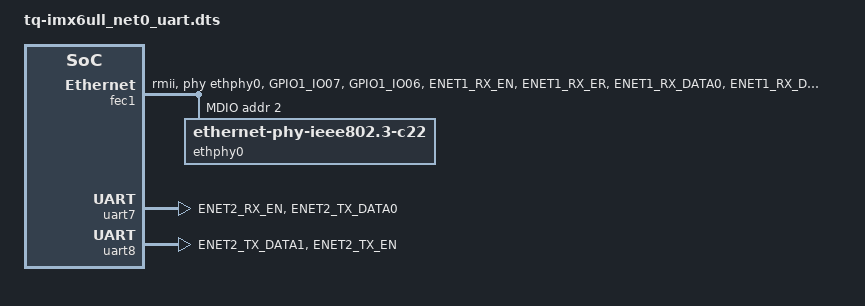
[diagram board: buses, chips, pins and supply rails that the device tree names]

#include "tq-imx6ull.dts"

&iomuxc {
	imx6ul-evk {
		pinctrl_enet1: enet1grp {
			fsl,pins = <
				MX6UL_PAD_GPIO1_IO07__ENET1_MDC		0x1b0b0
				MX6UL_PAD_GPIO1_IO06__ENET1_MDIO	0x1b0b0

				MX6UL_PAD_ENET1_RX_EN__ENET1_RX_EN	0x1b0b0
				MX6UL_PAD_ENET1_RX_ER__ENET1_RX_ER	0x1b0b0
				MX6UL_PAD_ENET1_RX_DATA0__ENET1_RDATA00	0x1b0b0
				MX6UL_PAD_ENET1_RX_DATA1__ENET1_RDATA01	0x1b0b0
				MX6UL_PAD_ENET1_TX_EN__ENET1_TX_EN	0x1b0b0
				MX6UL_PAD_ENET1_TX_DATA0__ENET1_TDATA00	0x1b0b0
				MX6UL_PAD_ENET1_TX_DATA1__ENET1_TDATA01	0x1b0b0
				MX6UL_PAD_ENET1_TX_CLK__ENET1_REF_CLK1	0x4001b031
			>;
		};

		pinctrl_uart8: uart8grp {
			fsl,pins = <
                MX6UL_PAD_ENET2_TX_DATA1__UART8_DCE_TX  0x1b0b1                  
                MX6UL_PAD_ENET2_TX_EN__UART8_DCE_RX  	0x1b0b1 
			>;
		};
		pinctrl_uart7: uart7grp {
			fsl,pins = <
                MX6UL_PAD_ENET2_RX_EN__UART7_DCE_TX     0x1b0b1 
                MX6UL_PAD_ENET2_TX_DATA0__UART7_DCE_RX  0x1b0b1       
			>;
		};
	};
};


&fec1 {
	pinctrl-names = "default";
	pinctrl-0 = <&pinctrl_enet1>;
	phy-mode = "rmii";
	phy-handle = <&ethphy0>;
	status = "okay";

	mdio {
		#address-cells = <1>;
		#size-cells = <0>;

		ethphy0: ethernet-phy@2 {
			compatible = "ethernet-phy-ieee802.3-c22";
			reg = <2>;
		};
	};

};


&fec2 {
	status = "disabled";
};

//to test uart7 uart8 remove R99~R102 R106 and add R32~R35.
&uart7 {
	pinctrl-names = "default";
	pinctrl-0 = <&pinctrl_uart7>;
	status = "okay";
};

&uart8 {
	pinctrl-names = "default";
	pinctrl-0 = <&pinctrl_uart8>;
	status = "okay";
};
